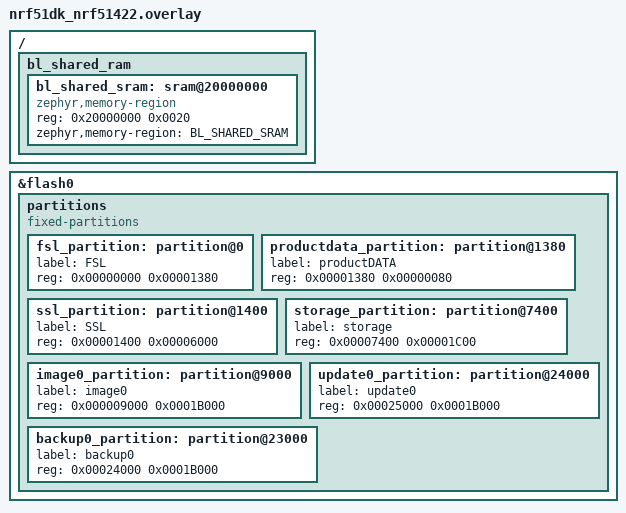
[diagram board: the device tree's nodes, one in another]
/*
 * Copyright (c) 2022 Laczen
 *
 * SPDX-License-Identifier: Apache-2.0
 */

#include "../app.overlay"

/delete-node/ &boot_partition;
/delete-node/ &slot0_partition;
/delete-node/ &slot1_partition;
/delete-node/ &storage_partition;

&flash0 {
	partitions {
		compatible = "fixed-partitions";
		#address-cells = <1>;
		#size-cells = <1>;

		fsl_partition: partition@0 {
			label = "FSL";
			reg = <0x00000000 0x00001380>;
		};

		productdata_partition: partition@1380 {
			label = "productDATA";
			reg = <0x00001380 0x00000080>;
		};

		ssl_partition: partition@1400 {
			label = "SSL";
			reg = <0x00001400 0x00006000>;
		};

		storage_partition: partition@7400 {
			label = "storage";
			reg = <0x00007400 0x00001C00>;
		};

		image0_partition: partition@9000 {
			label = "image0";
			reg = <0x000009000 0x0001B000>;
		};

		update0_partition: partition@24000 {
			label = "update0";
			reg = <0x00025000 0x0001B000>;
		};

		backup0_partition: partition@23000 {
			label = "backup0";
			reg = <0x00024000 0x0001B000>;
		};

	};
};

/ {
	bl_shared_ram {
		#address-cells = < 0x1 >;
		#size-cells = < 0x1 >;

		bl_shared_sram: sram@20000000 {
			compatible = "zephyr,memory-region", "mmio-sram";
			reg = < 0x20000000 0x0020 >;
			zephyr,memory-region = "BL_SHARED_SRAM";
		};
	};
};
